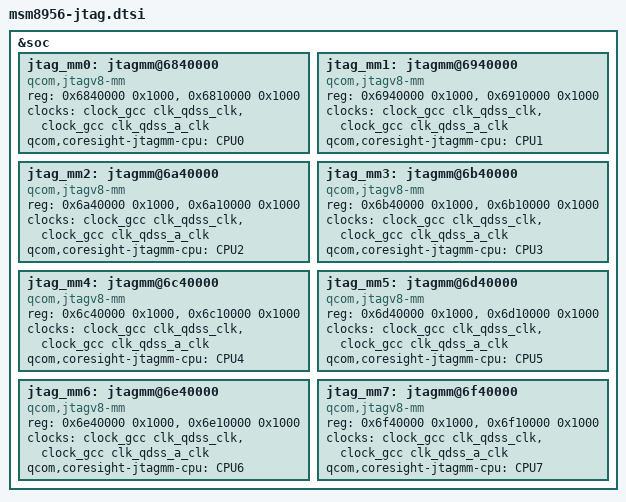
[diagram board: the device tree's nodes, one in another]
// SPDX-License-Identifier: GPL-2.0
// Copyright (c) 2014-2015, The Linux Foundation. All rights reserved.
// Copyright (c) 2022, Benarji Anand <benarji385@gmail.com>

&soc {
	jtag_mm0: jtagmm@6840000 {
		compatible = "qcom,jtagv8-mm";
		reg = <0x6840000 0x1000>,
		      <0x6810000 0x1000>;
		reg-names = "etm-base", "debug-base";

		clocks = <&clock_gcc clk_qdss_clk>,
		         <&clock_gcc clk_qdss_a_clk>;
		clock-names = "core_clk", "core_a_clk";

		qcom,coresight-jtagmm-cpu = <&CPU0>;
	};

	jtag_mm1: jtagmm@6940000 {
		compatible = "qcom,jtagv8-mm";
		reg = <0x6940000 0x1000>,
		      <0x6910000 0x1000>;
		reg-names = "etm-base", "debug-base";

		clocks = <&clock_gcc clk_qdss_clk>,
		         <&clock_gcc clk_qdss_a_clk>;
		clock-names = "core_clk", "core_a_clk";

		qcom,coresight-jtagmm-cpu = <&CPU1>;
	};

	jtag_mm2: jtagmm@6a40000 {
		compatible = "qcom,jtagv8-mm";
		reg = <0x6a40000 0x1000>,
		      <0x6a10000 0x1000>;
		reg-names = "etm-base", "debug-base";

		clocks = <&clock_gcc clk_qdss_clk>,
		         <&clock_gcc clk_qdss_a_clk>;
		clock-names = "core_clk", "core_a_clk";

		qcom,coresight-jtagmm-cpu = <&CPU2>;
	};

	jtag_mm3: jtagmm@6b40000 {
		compatible = "qcom,jtagv8-mm";
		reg = <0x6b40000 0x1000>,
		      <0x6b10000 0x1000>;
		reg-names = "etm-base", "debug-base";

		clocks = <&clock_gcc clk_qdss_clk>,
		         <&clock_gcc clk_qdss_a_clk>;
		clock-names = "core_clk", "core_a_clk";

		qcom,coresight-jtagmm-cpu = <&CPU3>;
	};

	jtag_mm4: jtagmm@6c40000 {
		compatible = "qcom,jtagv8-mm";
		reg = <0x6c40000 0x1000>,
		      <0x6c10000 0x1000>;
		reg-names = "etm-base", "debug-base";

		clocks = <&clock_gcc clk_qdss_clk>,
		         <&clock_gcc clk_qdss_a_clk>;
		clock-names = "core_clk", "core_a_clk";

		qcom,coresight-jtagmm-cpu = <&CPU4>;
	};

	jtag_mm5: jtagmm@6d40000 {
		compatible = "qcom,jtagv8-mm";
		reg = <0x6d40000 0x1000>,
		      <0x6d10000 0x1000>;
		reg-names = "etm-base", "debug-base";

		clocks = <&clock_gcc clk_qdss_clk>,
		         <&clock_gcc clk_qdss_a_clk>;
		clock-names = "core_clk", "core_a_clk";

		qcom,coresight-jtagmm-cpu = <&CPU5>;
	};

	jtag_mm6: jtagmm@6e40000 {
		compatible = "qcom,jtagv8-mm";
		reg = <0x6e40000 0x1000>,
		      <0x6e10000 0x1000>;
		reg-names = "etm-base", "debug-base";

		clocks = <&clock_gcc clk_qdss_clk>,
		         <&clock_gcc clk_qdss_a_clk>;
		clock-names = "core_clk", "core_a_clk";

		qcom,coresight-jtagmm-cpu = <&CPU6>;
	};

	jtag_mm7: jtagmm@6f40000 {
		compatible = "qcom,jtagv8-mm";
		reg = <0x6f40000 0x1000>,
		      <0x6f10000 0x1000>;
		reg-names = "etm-base", "debug-base";

		clocks = <&clock_gcc clk_qdss_clk>,
		         <&clock_gcc clk_qdss_a_clk>;
		clock-names = "core_clk", "core_a_clk";

		qcom,coresight-jtagmm-cpu = <&CPU7>;
	};
};
